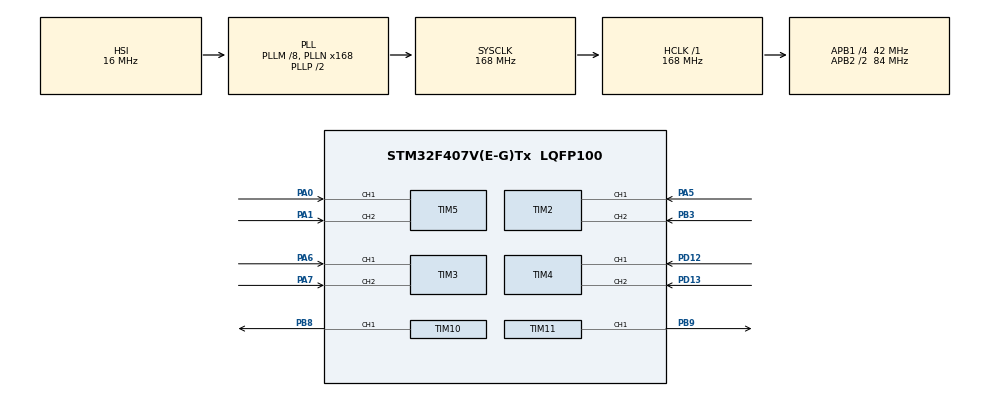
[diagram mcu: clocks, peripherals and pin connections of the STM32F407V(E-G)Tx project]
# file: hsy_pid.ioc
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Mcu.Family=STM32F4
Mcu.Name=STM32F407V(E-G)Tx
Mcu.Package=LQFP100
NVIC.PriorityGroup=NVIC_PRIORITYGROUP_4
PA0-WKUP.Signal=S_TIM5_CH1
PA1.Signal=S_TIM5_CH2
PA13.Mode=Serial_Wire
PA13.Signal=SYS_JTMS-SWDIO
PA14.Mode=Serial_Wire
PA14.Signal=SYS_JTCK-SWCLK
PA5.Signal=S_TIM2_CH1_ETR
PA6.Signal=S_TIM3_CH1
PA7.Signal=S_TIM3_CH2
PB3.Signal=S_TIM2_CH2
PB8.Signal=S_TIM10_CH1
PB9.Signal=S_TIM11_CH1
PD12.Signal=S_TIM4_CH1
PD13.Signal=S_TIM4_CH2
ProjectManager.HeapSize=0x200
ProjectManager.StackSize=0x400
ProjectManager.TargetToolchain=MDK-ARM V5.32
RCC.48MHZClocksFreq_Value=84000000
RCC.AHBFreq_Value=168000000
RCC.APB1CLKDivider=RCC_HCLK_DIV4
RCC.APB1Freq_Value=42000000
RCC.APB1TimFreq_Value=84000000
RCC.APB2CLKDivider=RCC_HCLK_DIV2
RCC.APB2Freq_Value=84000000
RCC.APB2TimFreq_Value=168000000
RCC.CortexFreq_Value=168000000
RCC.HCLKFreq_Value=168000000
RCC.HSE_VALUE=25000000
RCC.HSI_VALUE=16000000
RCC.LSE_VALUE=32768
RCC.PLLM=8
RCC.PLLN=168
RCC.SYSCLKFreq_VALUE=168000000
RCC.SYSCLKSource=RCC_SYSCLKSOURCE_PLLCLK
RCC.VCOOutputFreq_Value=336000000
SH.S_TIM10_CH1.0=TIM10_CH1,PWM Generation1 CH1
SH.S_TIM11_CH1.0=TIM11_CH1,PWM Generation1 CH1
SH.S_TIM2_CH1_ETR.0=TIM2_CH1,Encoder_Interface
SH.S_TIM2_CH2.0=TIM2_CH2,Encoder_Interface
SH.S_TIM3_CH1.0=TIM3_CH1,Encoder_Interface
SH.S_TIM3_CH2.0=TIM3_CH2,Encoder_Interface
SH.S_TIM4_CH1.0=TIM4_CH1,Encoder_Interface
SH.S_TIM4_CH2.0=TIM4_CH2,Encoder_Interface
SH.S_TIM5_CH1.0=TIM5_CH1,Encoder_Interface
SH.S_TIM5_CH2.0=TIM5_CH2,Encoder_Interface
TIM10.Channel=TIM_CHANNEL_1
TIM10.Period=2000-1
TIM10.Prescaler=1680-1
TIM11.Channel=TIM_CHANNEL_1
TIM11.Period=2000-1
TIM11.Prescaler=1680-1
VP_TIM10_VS_ClockSourceINT.Mode=Enable_Timer
VP_TIM11_VS_ClockSourceINT.Mode=Enable_Timer
board=custom

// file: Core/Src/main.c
/* USER CODE BEGIN Header */
/**
  ******************************************************************************
  * @file           : main.c
  * @brief          : Main program body
  ******************************************************************************
  * @attention
  *
  * Copyright (c) 2026 STMicroelectronics.
  * All rights reserved.
  *
  * This software is licensed under terms that can be found in the LICENSE file
  * in the root directory of this software component.
  * If no LICENSE file comes with this software, it is provided AS-IS.
  *
  ******************************************************************************
  */
/* USER CODE END Header */
#include "main.h"

/* USER CODE BEGIN Includes */
#include "speed_pid.h"
#include "motor.h"
/* USER CODE END Includes */

TIM_HandleTypeDef htim2;
TIM_HandleTypeDef htim3;
TIM_HandleTypeDef htim4;
TIM_HandleTypeDef htim5;
TIM_HandleTypeDef htim10;
TIM_HandleTypeDef htim11;

void SystemClock_Config(void);
static void MX_GPIO_Init(void);
static void MX_TIM10_Init(void);
static void MX_TIM11_Init(void);
static void MX_TIM2_Init(void);
static void MX_TIM3_Init(void);
static void MX_TIM4_Init(void);
static void MX_TIM5_Init(void);
/* USER CODE BEGIN PFP */
	int direct =0;
	int speed =200;
/* USER CODE END PFP */

int main(void)
{

  /* MCU Configuration--------------------------------------------------------*/

  /* Reset of all peripherals, Initializes the Flash interface and the Systick. */
  HAL_Init();

  /* Configure the system clock */
  SystemClock_Config();

  /* Initialize all configured peripherals */
  MX_GPIO_Init();
  MX_TIM10_Init();
  MX_TIM11_Init();
  MX_TIM2_Init();
  MX_TIM3_Init();
  MX_TIM4_Init();
  MX_TIM5_Init();
  /* USER CODE BEGIN 2 */
	HAL_TIM_PWM_Start(&htim10, TIM_CHANNEL_1);
	HAL_TIM_PWM_Start (&htim11,TIM_CHANNEL_1);

  /* USER CODE END 2 */

  /* Infinite loop */
  while (1)
  {
motor_zuohou(direct,speed);
  }
}

void SystemClock_Config(void)
{
  RCC_OscInitTypeDef RCC_OscInitStruct = {0};
  RCC_ClkInitTypeDef RCC_ClkInitStruct = {0};

  /** Configure the main internal regulator output voltage
  */
  __HAL_RCC_PWR_CLK_ENABLE();
  __HAL_PWR_VOLTAGESCALING_CONFIG(PWR_REGULATOR_VOLTAGE_SCALE1);

  /** Initializes the RCC Oscillators according to the specified parameters
  * in the RCC_OscInitTypeDef structure.
  */
  RCC_OscInitStruct.OscillatorType = RCC_OSCILLATORTYPE_HSI;
  RCC_OscInitStruct.HSIState = RCC_HSI_ON;
  RCC_OscInitStruct.HSICalibrationValue = RCC_HSICALIBRATION_DEFAULT;
  RCC_OscInitStruct.PLL.PLLState = RCC_PLL_ON;
  RCC_OscInitStruct.PLL.PLLSource = RCC_PLLSOURCE_HSI;
  RCC_OscInitStruct.PLL.PLLM = 8;
  RCC_OscInitStruct.PLL.PLLN = 168;
  RCC_OscInitStruct.PLL.PLLP = RCC_PLLP_DIV2;
  RCC_OscInitStruct.PLL.PLLQ = 4;
  if (HAL_RCC_OscConfig(&RCC_OscInitStruct) != HAL_OK)
  {
    Error_Handler();
  }

  /** Initializes the CPU, AHB and APB buses clocks
  */
  RCC_ClkInitStruct.ClockType = RCC_CLOCKTYPE_HCLK|RCC_CLOCKTYPE_SYSCLK
                              |RCC_CLOCKTYPE_PCLK1|RCC_CLOCKTYPE_PCLK2;
  RCC_ClkInitStruct.SYSCLKSource = RCC_SYSCLKSOURCE_PLLCLK;
  RCC_ClkInitStruct.AHBCLKDivider = RCC_SYSCLK_DIV1;
  RCC_ClkInitStruct.APB1CLKDivider = RCC_HCLK_DIV4;
  RCC_ClkInitStruct.APB2CLKDivider = RCC_HCLK_DIV2;

  if (HAL_RCC_ClockConfig(&RCC_ClkInitStruct, FLASH_LATENCY_5) != HAL_OK)
  {
    Error_Handler();
  }
}

static void MX_TIM2_Init(void)
{

  TIM_Encoder_InitTypeDef sConfig = {0};
  TIM_MasterConfigTypeDef sMasterConfig = {0};

  htim2.Instance = TIM2;
  htim2.Init.Prescaler = 0;
  htim2.Init.CounterMode = TIM_COUNTERMODE_UP;
  htim2.Init.Period = 4294967295;
  htim2.Init.ClockDivision = TIM_CLOCKDIVISION_DIV1;
  htim2.Init.AutoReloadPreload = TIM_AUTORELOAD_PRELOAD_DISABLE;
  sConfig.EncoderMode = TIM_ENCODERMODE_TI1;
  sConfig.IC1Polarity = TIM_ICPOLARITY_RISING;
  sConfig.IC1Selection = TIM_ICSELECTION_DIRECTTI;
  sConfig.IC1Prescaler = TIM_ICPSC_DIV1;
  sConfig.IC1Filter = 0;
  sConfig.IC2Polarity = TIM_ICPOLARITY_RISING;
  sConfig.IC2Selection = TIM_ICSELECTION_DIRECTTI;
  sConfig.IC2Prescaler = TIM_ICPSC_DIV1;
  sConfig.IC2Filter = 0;
  if (HAL_TIM_Encoder_Init(&htim2, &sConfig) != HAL_OK)
  {
    Error_Handler();
  }
  sMasterConfig.MasterOutputTrigger = TIM_TRGO_RESET;
  sMasterConfig.MasterSlaveMode = TIM_MASTERSLAVEMODE_DISABLE;
  if (HAL_TIMEx_MasterConfigSynchronization(&htim2, &sMasterConfig) != HAL_OK)
  {
    Error_Handler();
  }

}

static void MX_TIM3_Init(void)
{

  TIM_Encoder_InitTypeDef sConfig = {0};
  TIM_MasterConfigTypeDef sMasterConfig = {0};

  htim3.Instance = TIM3;
  htim3.Init.Prescaler = 0;
  htim3.Init.CounterMode = TIM_COUNTERMODE_UP;
  htim3.Init.Period = 65535;
  htim3.Init.ClockDivision = TIM_CLOCKDIVISION_DIV1;
  htim3.Init.AutoReloadPreload = TIM_AUTORELOAD_PRELOAD_DISABLE;
  sConfig.EncoderMode = TIM_ENCODERMODE_TI1;
  sConfig.IC1Polarity = TIM_ICPOLARITY_RISING;
  sConfig.IC1Selection = TIM_ICSELECTION_DIRECTTI;
  sConfig.IC1Prescaler = TIM_ICPSC_DIV1;
  sConfig.IC1Filter = 0;
  sConfig.IC2Polarity = TIM_ICPOLARITY_RISING;
  sConfig.IC2Selection = TIM_ICSELECTION_DIRECTTI;
  sConfig.IC2Prescaler = TIM_ICPSC_DIV1;
  sConfig.IC2Filter = 0;
  if (HAL_TIM_Encoder_Init(&htim3, &sConfig) != HAL_OK)
  {
    Error_Handler();
  }
  sMasterConfig.MasterOutputTrigger = TIM_TRGO_RESET;
  sMasterConfig.MasterSlaveMode = TIM_MASTERSLAVEMODE_DISABLE;
  if (HAL_TIMEx_MasterConfigSynchronization(&htim3, &sMasterConfig) != HAL_OK)
  {
    Error_Handler();
  }

}

static void MX_TIM4_Init(void)
{

  TIM_Encoder_InitTypeDef sConfig = {0};
  TIM_MasterConfigTypeDef sMasterConfig = {0};

  htim4.Instance = TIM4;
  htim4.Init.Prescaler = 0;
  htim4.Init.CounterMode = TIM_COUNTERMODE_UP;
  htim4.Init.Period = 65535;
  htim4.Init.ClockDivision = TIM_CLOCKDIVISION_DIV1;
  htim4.Init.AutoReloadPreload = TIM_AUTORELOAD_PRELOAD_DISABLE;
  sConfig.EncoderMode = TIM_ENCODERMODE_TI1;
  sConfig.IC1Polarity = TIM_ICPOLARITY_RISING;
  sConfig.IC1Selection = TIM_ICSELECTION_DIRECTTI;
  sConfig.IC1Prescaler = TIM_ICPSC_DIV1;
  sConfig.IC1Filter = 0;
  sConfig.IC2Polarity = TIM_ICPOLARITY_RISING;
  sConfig.IC2Selection = TIM_ICSELECTION_DIRECTTI;
  sConfig.IC2Prescaler = TIM_ICPSC_DIV1;
  sConfig.IC2Filter = 0;
  if (HAL_TIM_Encoder_Init(&htim4, &sConfig) != HAL_OK)
  {
    Error_Handler();
  }
  sMasterConfig.MasterOutputTrigger = TIM_TRGO_RESET;
  sMasterConfig.MasterSlaveMode = TIM_MASTERSLAVEMODE_DISABLE;
  if (HAL_TIMEx_MasterConfigSynchronization(&htim4, &sMasterConfig) != HAL_OK)
  {
    Error_Handler();
  }

}

static void MX_TIM5_Init(void)
{

  TIM_Encoder_InitTypeDef sConfig = {0};
  TIM_MasterConfigTypeDef sMasterConfig = {0};

  htim5.Instance = TIM5;
  htim5.Init.Prescaler = 0;
  htim5.Init.CounterMode = TIM_COUNTERMODE_UP;
  htim5.Init.Period = 4294967295;
  htim5.Init.ClockDivision = TIM_CLOCKDIVISION_DIV1;
  htim5.Init.AutoReloadPreload = TIM_AUTORELOAD_PRELOAD_DISABLE;
  sConfig.EncoderMode = TIM_ENCODERMODE_TI1;
  sConfig.IC1Polarity = TIM_ICPOLARITY_RISING;
  sConfig.IC1Selection = TIM_ICSELECTION_DIRECTTI;
  sConfig.IC1Prescaler = TIM_ICPSC_DIV1;
  sConfig.IC1Filter = 0;
  sConfig.IC2Polarity = TIM_ICPOLARITY_RISING;
  sConfig.IC2Selection = TIM_ICSELECTION_DIRECTTI;
  sConfig.IC2Prescaler = TIM_ICPSC_DIV1;
  sConfig.IC2Filter = 0;
  if (HAL_TIM_Encoder_Init(&htim5, &sConfig) != HAL_OK)
  {
    Error_Handler();
  }
  sMasterConfig.MasterOutputTrigger = TIM_TRGO_RESET;
  sMasterConfig.MasterSlaveMode = TIM_MASTERSLAVEMODE_DISABLE;
  if (HAL_TIMEx_MasterConfigSynchronization(&htim5, &sMasterConfig) != HAL_OK)
  {
    Error_Handler();
  }

}

static void MX_TIM10_Init(void)
{

  TIM_OC_InitTypeDef sConfigOC = {0};

  htim10.Instance = TIM10;
  htim10.Init.Prescaler = 1680-1;
  htim10.Init.CounterMode = TIM_COUNTERMODE_UP;
  htim10.Init.Period = 2000-1;
  htim10.Init.ClockDivision = TIM_CLOCKDIVISION_DIV1;
  htim10.Init.AutoReloadPreload = TIM_AUTORELOAD_PRELOAD_DISABLE;
  if (HAL_TIM_Base_Init(&htim10) != HAL_OK)
  {
    Error_Handler();
  }
  if (HAL_TIM_PWM_Init(&htim10) != HAL_OK)
  {
    Error_Handler();
  }
  sConfigOC.OCMode = TIM_OCMODE_PWM1;
  sConfigOC.Pulse = 0;
  sConfigOC.OCPolarity = TIM_OCPOLARITY_HIGH;
  sConfigOC.OCFastMode = TIM_OCFAST_DISABLE;
  if (HAL_TIM_PWM_ConfigChannel(&htim10, &sConfigOC, TIM_CHANNEL_1) != HAL_OK)
  {
    Error_Handler();
  }
  HAL_TIM_MspPostInit(&htim10);

}

static void MX_TIM11_Init(void)
{

  TIM_OC_InitTypeDef sConfigOC = {0};

  htim11.Instance = TIM11;
  htim11.Init.Prescaler = 1680-1;
  htim11.Init.CounterMode = TIM_COUNTERMODE_UP;
  htim11.Init.Period = 2000-1;
  htim11.Init.ClockDivision = TIM_CLOCKDIVISION_DIV1;
  htim11.Init.AutoReloadPreload = TIM_AUTORELOAD_PRELOAD_DISABLE;
  if (HAL_TIM_Base_Init(&htim11) != HAL_OK)
  {
    Error_Handler();
  }
  if (HAL_TIM_PWM_Init(&htim11) != HAL_OK)
  {
    Error_Handler();
  }
  sConfigOC.OCMode = TIM_OCMODE_PWM1;
  sConfigOC.Pulse = 0;
  sConfigOC.OCPolarity = TIM_OCPOLARITY_HIGH;
  sConfigOC.OCFastMode = TIM_OCFAST_DISABLE;
  if (HAL_TIM_PWM_ConfigChannel(&htim11, &sConfigOC, TIM_CHANNEL_1) != HAL_OK)
  {
    Error_Handler();
  }
  HAL_TIM_MspPostInit(&htim11);

}

static void MX_GPIO_Init(void)
{

  /* GPIO Ports Clock Enable */
  __HAL_RCC_GPIOA_CLK_ENABLE();
  __HAL_RCC_GPIOD_CLK_ENABLE();
  __HAL_RCC_GPIOB_CLK_ENABLE();

}

void Error_Handler(void)
{
  __disable_irq();
  while (1)
  {
  }
}
